# RockChip_RK3588 register map
Vendor: RockChip Electronics Co., Ltd.; Series: RK3588; File version: 0.1
Registers are 32-bit, read-write, no defined reset value unless marked. A register's access mark holds for its fields unless they carry their own. Offsets are from the block's base; [hi:lo] are bit positions; {n}, {i} and the like mark numbered series.

## CRU (part 3 of 6)
Base 0xFD7C0000
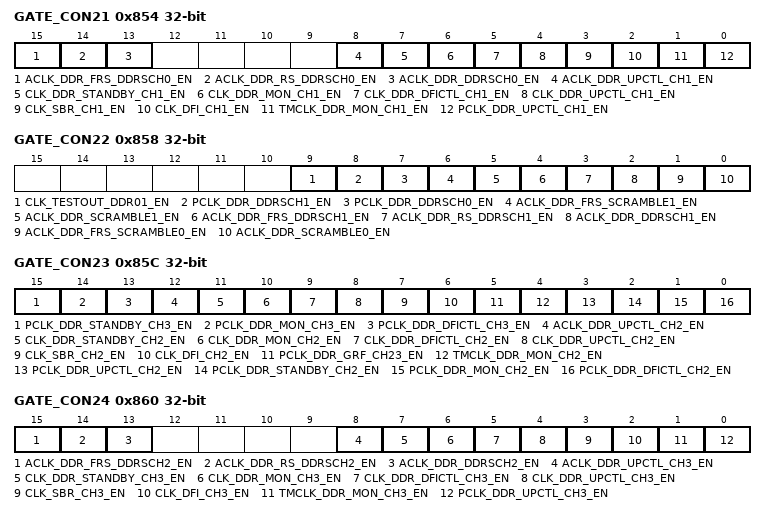
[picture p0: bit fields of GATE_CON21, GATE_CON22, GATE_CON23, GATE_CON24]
0x854 GATE_CON21 — Internal clock gate and division register 21
  [all] fields
    1=DISABLE; 0=ENABLE
  [15] ACLK_DDR_FRS_DDRSCH0_EN — aclk_ddr_frs_ddrsch0 clock gating control.
  [14] ACLK_DDR_RS_DDRSCH0_EN — aclk_ddr_rs_ddrsch0 clock gating control.
  [13] ACLK_DDR_DDRSCH0_EN — aclk_ddr_ddrsch0 clock gating control.
  [8] ACLK_DDR_UPCTL_CH1_EN — aclk_ddr_upctl_ch1 clock gating control.
  [7] CLK_DDR_STANDBY_CH1_EN — clk_ddr_standby_ch1 clock gating control.
  [6] CLK_DDR_MON_CH1_EN — clk_ddr_mon_ch1 clock gating control.
  [5] CLK_DDR_DFICTL_CH1_EN — clk_ddr_dfictl_ch1 clock gating control.
  [4] CLK_DDR_UPCTL_CH1_EN — clk_ddr_upctl_ch1 clock gating control.
  [3] CLK_SBR_CH1_EN — clk_sbr_ch1 clock gating control.
  [2] CLK_DFI_CH1_EN — clk_dfi_ch1 clock gating control.
  [1] TMCLK_DDR_MON_CH1_EN — tmclk_ddr_mon_ch1 clock gating control.
  [0] PCLK_DDR_UPCTL_CH1_EN — pclk_ddr_upctl_ch1 clock gating control.
0x858 GATE_CON22 — Internal clock gate and division register 22
  [all] fields
    1=DISABLE; 0=ENABLE
  [9] CLK_TESTOUT_DDR01_EN — clk_testout_ddr01 clock gating control.
  [8] PCLK_DDR_DDRSCH1_EN — pclk_ddr_ddrsch1 clock gating control.
  [7] PCLK_DDR_DDRSCH0_EN — pclk_ddr_ddrsch0 clock gating control.
  [6] ACLK_DDR_FRS_SCRAMBLE1_EN — aclk_ddr_frs_scramble1 clock gating control.
  [5] ACLK_DDR_SCRAMBLE1_EN — aclk_ddr_scramble1 clock gating control.
  [4] ACLK_DDR_FRS_DDRSCH1_EN — aclk_ddr_frs_ddrsch1 clock gating control.
  [3] ACLK_DDR_RS_DDRSCH1_EN — aclk_ddr_rs_ddrsch1 clock gating control.
  [2] ACLK_DDR_DDRSCH1_EN — aclk_ddr_ddrsch1 clock gating control.
  [1] ACLK_DDR_FRS_SCRAMBLE0_EN — aclk_ddr_frs_scramble0 clock gating control.
  [0] ACLK_DDR_SCRAMBLE0_EN — aclk_ddr_scramble0 clock gating control.
0x85C GATE_CON23 — Internal clock gate and division register 23
  [all] fields
    1=DISABLE; 0=ENABLE
  [15] PCLK_DDR_STANDBY_CH3_EN — pclk_ddr_standby_ch3 clock gating control.
  [14] PCLK_DDR_MON_CH3_EN — pclk_ddr_mon_ch3 clock gating control.
  [13] PCLK_DDR_DFICTL_CH3_EN — pclk_ddr_dfictl_ch3 clock gating control.
  [12] ACLK_DDR_UPCTL_CH2_EN — aclk_ddr_upctl_ch2 clock gating control.
  [11] CLK_DDR_STANDBY_CH2_EN — clk_ddr_standby_ch2 clock gating control.
  [10] CLK_DDR_MON_CH2_EN — clk_ddr_mon_ch2 clock gating control.
  [9] CLK_DDR_DFICTL_CH2_EN — clk_ddr_dfictl_ch2 clock gating control.
  [8] CLK_DDR_UPCTL_CH2_EN — clk_ddr_upctl_ch2 clock gating control.
  [7] CLK_SBR_CH2_EN — clk_sbr_ch2 clock gating control.
  [6] CLK_DFI_CH2_EN — clk_dfi_ch2 clock gating control.
  [5] PCLK_DDR_GRF_CH23_EN — pclk_ddr_grf_ch23 clock gating control, both ddr ch2 and ddr ch3.
  [4] TMCLK_DDR_MON_CH2_EN — tmclk_ddr_mon_ch2 clock gating control.
  [3] PCLK_DDR_UPCTL_CH2_EN — pclk_ddr_upctl_ch2 clock gating control.
  [2] PCLK_DDR_STANDBY_CH2_EN — pclk_ddr_standby_ch2 clock gating control.
  [1] PCLK_DDR_MON_CH2_EN — pclk_ddr_mon_ch2 clock gating control.
  [0] PCLK_DDR_DFICTL_CH2_EN — pclk_ddr_dfictl_ch2 clock gating control.
0x860 GATE_CON24 — Internal clock gate and division register 24
  [all] fields
    1=DISABLE; 0=ENABLE
  [15] ACLK_DDR_FRS_DDRSCH2_EN — aclk_ddr_frs_ddrsch2 clock gating control.
  [14] ACLK_DDR_RS_DDRSCH2_EN — aclk_ddr_rs_ddrsch2 clock gating control.
  [13] ACLK_DDR_DDRSCH2_EN — aclk_ddr_ddrsch2 clock gating control.
  [8] ACLK_DDR_UPCTL_CH3_EN — aclk_ddr_upctl_ch3 clock gating control.
  [7] CLK_DDR_STANDBY_CH3_EN — clk_ddr_standby_ch3 clock gating control.
  [6] CLK_DDR_MON_CH3_EN — clk_ddr_mon_ch3 clock gating control.
  [5] CLK_DDR_DFICTL_CH3_EN — clk_ddr_dfictl_ch3 clock gating control.
  [4] CLK_DDR_UPCTL_CH3_EN — clk_ddr_upctl_ch3 clock gating control.
  [3] CLK_SBR_CH3_EN — clk_sbr_ch3 clock gating control.
  [2] CLK_DFI_CH3_EN — clk_dfi_ch3 clock gating control.
  [1] TMCLK_DDR_MON_CH3_EN — tmclk_ddr_mon_ch3 clock gating control.
  [0] PCLK_DDR_UPCTL_CH3_EN — pclk_ddr_upctl_ch3 clock gating control.
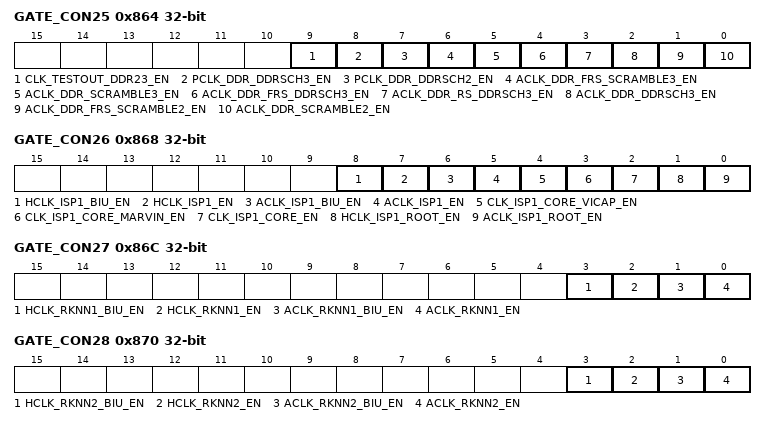
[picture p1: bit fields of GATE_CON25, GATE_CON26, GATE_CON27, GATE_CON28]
0x864 GATE_CON25 — Internal clock gate and division register 25
  [all] fields
    1=DISABLE; 0=ENABLE
  [9] CLK_TESTOUT_DDR23_EN — clk_testout_ddr23 clock gating control.
  [8] PCLK_DDR_DDRSCH3_EN — pclk_ddr_ddrsch3 clock gating control.
  [7] PCLK_DDR_DDRSCH2_EN — pclk_ddr_ddrsch2 clock gating control.
  [6] ACLK_DDR_FRS_SCRAMBLE3_EN — aclk_ddr_frs_scramble3 clock gating control.
  [5] ACLK_DDR_SCRAMBLE3_EN — aclk_ddr_scramble3 clock gating control.
  [4] ACLK_DDR_FRS_DDRSCH3_EN — aclk_ddr_frs_ddrsch3 clock gating control.
  [3] ACLK_DDR_RS_DDRSCH3_EN — aclk_ddr_rs_ddrsch3 clock gating control.
  [2] ACLK_DDR_DDRSCH3_EN — aclk_ddr_ddrsch3 clock gating control.
  [1] ACLK_DDR_FRS_SCRAMBLE2_EN — aclk_ddr_frs_scramble2 clock gating control.
  [0] ACLK_DDR_SCRAMBLE2_EN — aclk_ddr_scramble2 clock gating control.
0x868 GATE_CON26 — Internal clock gate and division register 26
  [all] fields
    1=DISABLE; 0=ENABLE
  [8] HCLK_ISP1_BIU_EN — hclk_isp1_biu clock gating control.
  [7] HCLK_ISP1_EN — hclk_isp1 clock gating control.
  [6] ACLK_ISP1_BIU_EN — aclk_isp1_biu clock gating control.
  [5] ACLK_ISP1_EN — aclk_isp1 clock gating control.
  [4] CLK_ISP1_CORE_VICAP_EN — clk_isp1_core_vicap clock gating control.
  [3] CLK_ISP1_CORE_MARVIN_EN — clk_isp1_core_marvin clock gating control.
  [2] CLK_ISP1_CORE_EN — clk_isp1_core clock gating control.
  [1] HCLK_ISP1_ROOT_EN — hclk_isp1_root clock gating control.
  [0] ACLK_ISP1_ROOT_EN — aclk_isp1_root clock gating control.
0x86C GATE_CON27 — Internal clock gate and division register 27
  [all] fields
    1=DISABLE; 0=ENABLE
  [3] HCLK_RKNN1_BIU_EN — hclk_rknn1_biu clock gating control.
  [2] HCLK_RKNN1_EN — hclk_rknn1 clock gating control.
  [1] ACLK_RKNN1_BIU_EN — aclk_rknn1_biu clock gating control.
  [0] ACLK_RKNN1_EN — aclk_rknn1 clock gating control.
0x870 GATE_CON28 — Internal clock gate and division register 28
  [all] fields
    1=DISABLE; 0=ENABLE
  [3] HCLK_RKNN2_BIU_EN — hclk_rknn2_biu clock gating control.
  [2] HCLK_RKNN2_EN — hclk_rknn2 clock gating control.
  [1] ACLK_RKNN2_BIU_EN — aclk_rknn2_biu clock gating control.
  [0] ACLK_RKNN2_EN — aclk_rknn2 clock gating control.
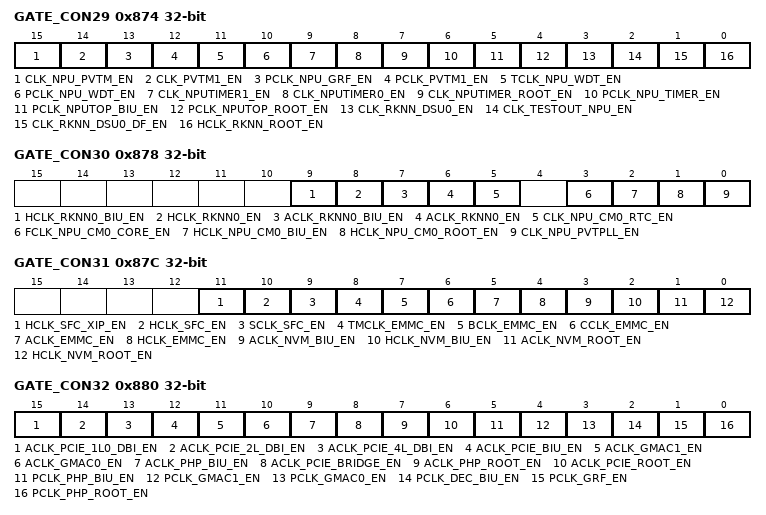
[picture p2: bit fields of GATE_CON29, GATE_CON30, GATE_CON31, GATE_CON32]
0x874 GATE_CON29 — Internal clock gate and division register 29
  [all] fields
    1=DISABLE; 0=ENABLE
  [15] CLK_NPU_PVTM_EN — clk_npu_pvtm clock gating control.
  [14] CLK_PVTM1_EN — clk_pvtm1 clock gating control.
  [13] PCLK_NPU_GRF_EN — pclk_npu_grf clock gating control.
  [12] PCLK_PVTM1_EN — pclk_pvtm1 clock gating control.
  [11] TCLK_NPU_WDT_EN — tclk_npu_wdt clock gating control.
  [10] PCLK_NPU_WDT_EN — pclk_npu_wdt clock gating control.
  [9] CLK_NPUTIMER1_EN — clk_nputimer1 clock gating control.
  [8] CLK_NPUTIMER0_EN — clk_nputimer0 clock gating control.
  [7] CLK_NPUTIMER_ROOT_EN — clk_nputimer_root clock gating control.
  [6] PCLK_NPU_TIMER_EN — pclk_npu_timer clock gating control.
  [5] PCLK_NPUTOP_BIU_EN — pclk_nputop_biu clock gating control.
  [4] PCLK_NPUTOP_ROOT_EN — pclk_nputop_root clock gating control.
  [3] CLK_RKNN_DSU0_EN — clk_rknn_dsu0 clock gating control.
  [2] CLK_TESTOUT_NPU_EN — clk_testout_npu clock gating control.
  [1] CLK_RKNN_DSU0_DF_EN — clk_rknn_dsu0_src_t clock gating control.
  [0] HCLK_RKNN_ROOT_EN — hclk_rknn_root clock gating control.
0x878 GATE_CON30 — Internal clock gate and division register 30
  [all] fields
    1=DISABLE; 0=ENABLE
  [9] HCLK_RKNN0_BIU_EN — hclk_rknn0_biu clock gating control.
  [8] HCLK_RKNN0_EN — hclk_rknn0 clock gating control.
  [7] ACLK_RKNN0_BIU_EN — aclk_rknn0_biu clock gating control.
  [6] ACLK_RKNN0_EN — aclk_rknn0 clock gating control.
  [5] CLK_NPU_CM0_RTC_EN — clk_npu_cm0_rtc clock gating control.
  [3] FCLK_NPU_CM0_CORE_EN — fclk_npu_cm0_core clock gating control.
  [2] HCLK_NPU_CM0_BIU_EN — hclk_npu_cm0_biu clock gating control.
  [1] HCLK_NPU_CM0_ROOT_EN — hclk_npu_cm0_root clock gating control.
  [0] CLK_NPU_PVTPLL_EN — clk_npu_pvtpll clock gating control.
0x87C GATE_CON31 — Internal clock gate and division register 31
  [all] fields
    1=DISABLE; 0=ENABLE
  [11] HCLK_SFC_XIP_EN — hclk_sfc_xip clock gating control.
  [10] HCLK_SFC_EN — hclk_sfc clock gating control.
  [9] SCLK_SFC_EN — sclk_sfc clock gating control.
  [8] TMCLK_EMMC_EN — tmclk_emmc clock gating control.
  [7] BCLK_EMMC_EN — bclk_emmc clock gating control.
  [6] CCLK_EMMC_EN — cclk_emmc clock gating control.
  [5] ACLK_EMMC_EN — aclk_emmc clock gating control.
  [4] HCLK_EMMC_EN — hclk_emmc clock gating control.
  [3] ACLK_NVM_BIU_EN — aclk_nvm_biu clock gating control.
  [2] HCLK_NVM_BIU_EN — hclk_nvm_biu clock gating control.
  [1] ACLK_NVM_ROOT_EN — aclk_nvm_root clock gating control.
  [0] HCLK_NVM_ROOT_EN — hclk_nvm_root clock gating control.
0x880 GATE_CON32 — Internal clock gate and division register 32
  [all] fields
    1=DISABLE; 0=ENABLE
  [15] ACLK_PCIE_1L0_DBI_EN — aclk_pcie_1l0_dbi clock gating control.
  [14] ACLK_PCIE_2L_DBI_EN — aclk_pcie_2l_dbi clock gating control.
  [13] ACLK_PCIE_4L_DBI_EN — aclk_pcie_4l_dbi clock gating control.
  [12] ACLK_PCIE_BIU_EN — aclk_pcie_biu clock gating control.
  [11] ACLK_GMAC1_EN — aclk_gmac1 clock gating control.
  [10] ACLK_GMAC0_EN — aclk_gmac0 clock gating control.
  [9] ACLK_PHP_BIU_EN — aclk_php_biu clock gating control.
  [8] ACLK_PCIE_BRIDGE_EN — aclk_pcie_gridge clock gating control.
  [7] ACLK_PHP_ROOT_EN — aclk_php_root clock gating control.
  [6] ACLK_PCIE_ROOT_EN — aclk_pcie_root clock gating control.
  [5] PCLK_PHP_BIU_EN — pclk_php_biu clock gating control.
  [4] PCLK_GMAC1_EN — pclk_gmac1 clock gating control.
  [3] PCLK_GMAC0_EN — pclk_gmac0 clock gating control.
  [2] PCLK_DEC_BIU_EN — pclk_dec_biu clock gating control.
  [1] PCLK_GRF_EN — pclk_grf clock gating control.
  [0] PCLK_PHP_ROOT_EN — pclk_php_root clock gating control.
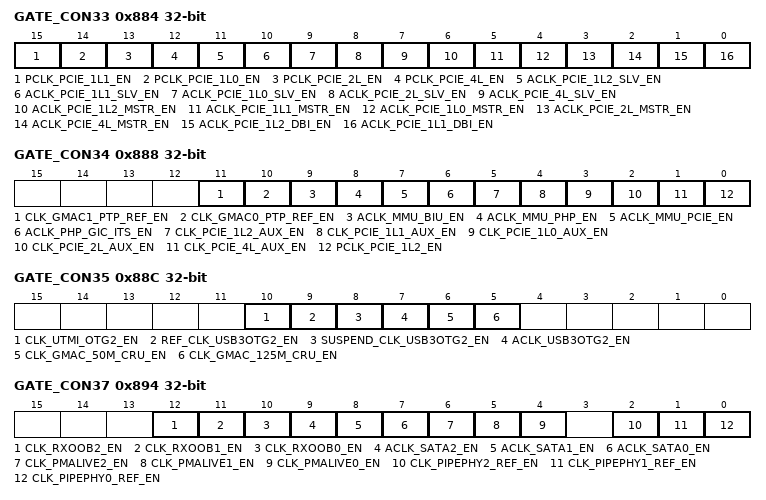
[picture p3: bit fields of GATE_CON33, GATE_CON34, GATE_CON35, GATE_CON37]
0x884 GATE_CON33 — Internal clock gate and division register 33
  [all] fields
    1=DISABLE; 0=ENABLE
  [15] PCLK_PCIE_1L1_EN — pclk_pcie_1l1 clock gating control.
  [14] PCLK_PCIE_1L0_EN — pclk_pcie_1l0 clock gating control.
  [13] PCLK_PCIE_2L_EN — pclk_pcie_2l clock gating control.
  [12] PCLK_PCIE_4L_EN — pclk_pcie_4l clock gating control.
  [11] ACLK_PCIE_1L2_SLV_EN — aclk_pcie_1l2_slv clock gating control.
  [10] ACLK_PCIE_1L1_SLV_EN — aclk_pcie_1l1_slv clock gating control.
  [9] ACLK_PCIE_1L0_SLV_EN — aclk_pcie_1l0_slv clock gating control.
  [8] ACLK_PCIE_2L_SLV_EN — aclk_pcie_2l_slv clock gating control.
  [7] ACLK_PCIE_4L_SLV_EN — aclk_pcie_4l_slv clock gating control.
  [6] ACLK_PCIE_1L2_MSTR_EN — aclk_pcie_1l2_mstr clock gating control.
  [5] ACLK_PCIE_1L1_MSTR_EN — aclk_pcie_1l1_mstr clock gating control.
  [4] ACLK_PCIE_1L0_MSTR_EN — aclk_pcie_1l0_mstr clock gating control.
  [3] ACLK_PCIE_2L_MSTR_EN — aclk_pcie_2l_mstr clock gating control.
  [2] ACLK_PCIE_4L_MSTR_EN — aclk_pcie_4l_mstr clock gating control.
  [1] ACLK_PCIE_1L2_DBI_EN — aclk_pcie_1l2_dbi clock gating control.
  [0] ACLK_PCIE_1L1_DBI_EN — aclk_pcie_1l1_dbi clock gating control.
0x888 GATE_CON34 — Internal clock gate and division register 34
  [all] fields
    1=DISABLE; 0=ENABLE
  [11] CLK_GMAC1_PTP_REF_EN — clk_gmac1_ptp_ref clock gating control.
  [10] CLK_GMAC0_PTP_REF_EN — clk_gmac0_ptp_ref clock gating control.
  [9] ACLK_MMU_BIU_EN — aclk_mmu_biu clock gating control.
  [8] ACLK_MMU_PHP_EN — aclk_mmu_php clock gating control.
  [7] ACLK_MMU_PCIE_EN — aclk_mmu_pcie clock gating control.
  [6] ACLK_PHP_GIC_ITS_EN — aclk_php_gic_its clock gating control.
  [5] CLK_PCIE_1L2_AUX_EN — clk_pcie_1l2_aux clock gating control.
  [4] CLK_PCIE_1L1_AUX_EN — clk_pcie_1l1_aux clock gating control.
  [3] CLK_PCIE_1L0_AUX_EN — clk_pcie_1l0_aux clock gating control.
  [2] CLK_PCIE_2L_AUX_EN — clk_pcie_2l_aux clock gating control.
  [1] CLK_PCIE_4L_AUX_EN — clk_pcie_4l_aux clock gating control.
  [0] PCLK_PCIE_1L2_EN — pclk_pcie_1l2 clock gating control.
0x88C GATE_CON35 — Internal clock gate and division register 35
  [all] fields
    1=DISABLE; 0=ENABLE
  [10] CLK_UTMI_OTG2_EN — clk_utmi_otg2 clock gating control.
  [9] REF_CLK_USB3OTG2_EN — ref_clk_usb3otg2 clock gating control.
  [8] SUSPEND_CLK_USB3OTG2_EN — suspend_clk_usb3otg2 clock gating control.
  [7] ACLK_USB3OTG2_EN — aclk_usb3otg2 clock gating control.
  [6] CLK_GMAC_50M_CRU_EN — clk_gmac_50m_cru_i clock gating control.
  [5] CLK_GMAC_125M_CRU_EN — clk_gmac_125m_cru_i clock gating control.
0x894 GATE_CON37 — Internal clock gate and division register 37
  [all] fields
    1=DISABLE; 0=ENABLE
  [12] CLK_RXOOB2_EN — clk_rxoob2 clock gating control.
  [11] CLK_RXOOB1_EN — clk_rxoob1 clock gating control.
  [10] CLK_RXOOB0_EN — clk_rxoob0 clock gating control.
  [9] ACLK_SATA2_EN — aclk_sata2 clock gating control.
  [8] ACLK_SATA1_EN — aclk_sata1 clock gating control.
  [7] ACLK_SATA0_EN — aclk_sata0 clock gating control.
  [6] CLK_PMALIVE2_EN — clk_pmalive2 clock gating control.
  [5] CLK_PMALIVE1_EN — clk_pmalive1 clock gating control.
  [4] CLK_PMALIVE0_EN — clk_pmalive0 clock gating control.
  [2] CLK_PIPEPHY2_REF_EN — clk_pipephy2_ref clock gating control.
  [1] CLK_PIPEPHY1_REF_EN — clk_pipephy1_ref clock gating control.
  [0] CLK_PIPEPHY0_REF_EN — clk_pipephy0_ref clock gating control.
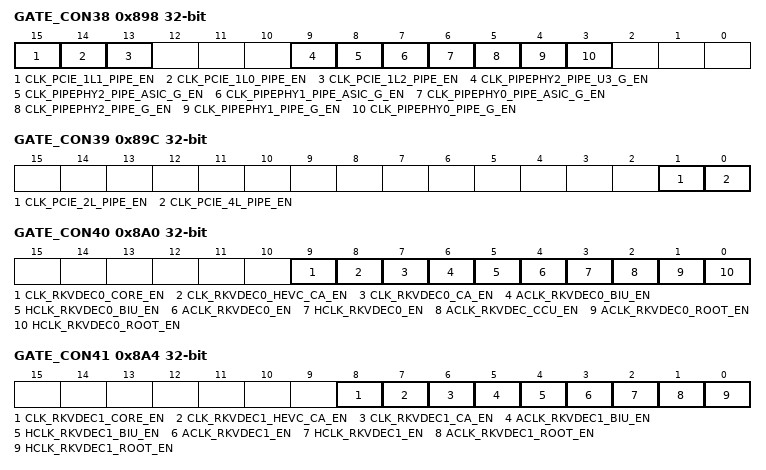
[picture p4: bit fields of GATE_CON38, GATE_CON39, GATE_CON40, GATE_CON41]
0x898 GATE_CON38 — Internal clock gate and division register 38
  [all] fields
    1=DISABLE; 0=ENABLE
  [15] CLK_PCIE_1L1_PIPE_EN — clk_pcie_1l1_pipe clock gating control.
  [14] CLK_PCIE_1L0_PIPE_EN — clk_pcie_1l0_pipe clock gating control.
  [13] CLK_PCIE_1L2_PIPE_EN — clk_pcie_1l2_pipe clock gating control.
  [9] CLK_PIPEPHY2_PIPE_U3_G_EN — clk_pipephy2_pipe_u3_g clock gating control.
  [8] CLK_PIPEPHY2_PIPE_ASIC_G_EN — clk_pipephy2_pipe_asic_g clock gating control.
  [7] CLK_PIPEPHY1_PIPE_ASIC_G_EN — clk_pipephy1_pipe_asic_g clock gating control.
  [6] CLK_PIPEPHY0_PIPE_ASIC_G_EN — clk_pipephy0_pipe_asic_g clock gating control.
  [5] CLK_PIPEPHY2_PIPE_G_EN — clk_pipephy2_pipe_g clock gating control.
  [4] CLK_PIPEPHY1_PIPE_G_EN — clk_pipephy1_pipe_g clock gating control.
  [3] CLK_PIPEPHY0_PIPE_G_EN — clk_pipephy0_pipe_g clock gating control.
0x89C GATE_CON39 — Internal clock gate and division register 39
  [1] CLK_PCIE_2L_PIPE_EN — clk_pcie_2l_pipe clock gating control.
    1=DISABLE; 0=ENABLE
  [0] CLK_PCIE_4L_PIPE_EN — clk_pcie_4l_pipe clock gating control.
    1=DISABLE; 0=ENABLE
0x8A0 GATE_CON40 — Internal clock gate and division register 40
  [all] fields
    1=DISABLE; 0=ENABLE
  [9] CLK_RKVDEC0_CORE_EN — clk_rkvdec0_core clock gating control.
  [8] CLK_RKVDEC0_HEVC_CA_EN — clk_rkvdec0_hevc_ca clock gating control.
  [7] CLK_RKVDEC0_CA_EN — clk_rkvdec0_ca clock gating control.
  [6] ACLK_RKVDEC0_BIU_EN — aclk_rkvdec0_biu clock gating control.
  [5] HCLK_RKVDEC0_BIU_EN — hclk_rkvdec0_biu clock gating control.
  [4] ACLK_RKVDEC0_EN — aclk_rkvdec0 clock gating control.
  [3] HCLK_RKVDEC0_EN — hclk_rkvdec0 clock gating control.
  [2] ACLK_RKVDEC_CCU_EN — aclk_rkvdec_ccu clock gating control.
  [1] ACLK_RKVDEC0_ROOT_EN — aclk_rkvdec0_root clock gating control.
  [0] HCLK_RKVDEC0_ROOT_EN — hclk_rkvdec0_root clock gating control.
0x8A4 GATE_CON41 — Internal clock gate and division register 41
  [all] fields
    1=DISABLE; 0=ENABLE
  [8] CLK_RKVDEC1_CORE_EN — clk_rkvdec1_core clock gating control.
  [7] CLK_RKVDEC1_HEVC_CA_EN — clk_rkvdec1_hevc_ca clock gating control.
  [6] CLK_RKVDEC1_CA_EN — clk_rkvdec1_ca clock gating control.
  [5] ACLK_RKVDEC1_BIU_EN — aclk_rkvdec1_biu clock gating control.
  [4] HCLK_RKVDEC1_BIU_EN — hclk_rkvdec1_biu clock gating control.
  [3] ACLK_RKVDEC1_EN — aclk_rkvdec1 clock gating control.
  [2] HCLK_RKVDEC1_EN — hclk_rkvdec1 clock gating control.
  [1] ACLK_RKVDEC1_ROOT_EN — aclk_rkvdec1_root clock gating control.
  [0] HCLK_RKVDEC1_ROOT_EN — hclk_rkvdec1_root clock gating control.
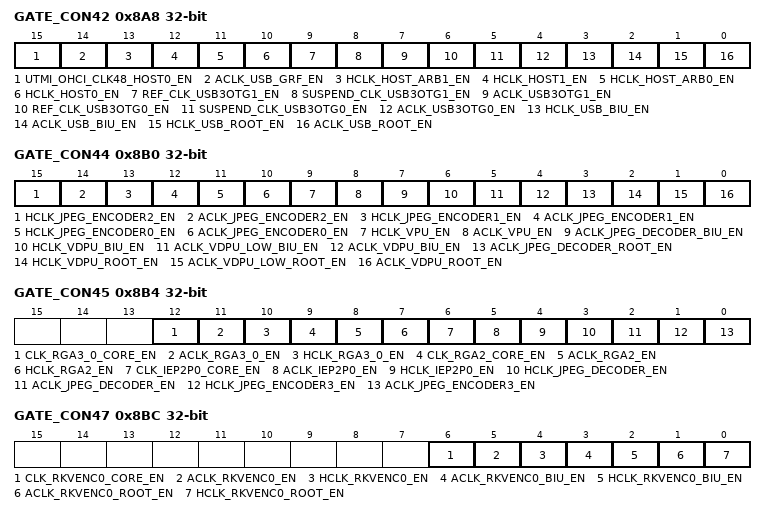
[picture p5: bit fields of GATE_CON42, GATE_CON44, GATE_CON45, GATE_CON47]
0x8A8 GATE_CON42 — Internal clock gate and division register 42
  [all] fields
    1=DISABLE; 0=ENABLE
  [15] UTMI_OHCI_CLK48_HOST0_EN — utmi_ohci_clk48_host0 clock gating control.
  [14] ACLK_USB_GRF_EN — aclk_usb_grf clock gating control.
  [13] HCLK_HOST_ARB1_EN — hclk_host_arb1 clock gating control.
  [12] HCLK_HOST1_EN — hclk_host1 clock gating control.
  [11] HCLK_HOST_ARB0_EN — hclk_host_arb0 clock gating control.
  [10] HCLK_HOST0_EN — hclk_host0 clock gating control.
  [9] REF_CLK_USB3OTG1_EN — ref_clk_usb3otg1 clock gating control.
  [8] SUSPEND_CLK_USB3OTG1_EN — suspend_clk_usb3otg1 clock gating control.
  [7] ACLK_USB3OTG1_EN — aclk_usb3otg1 clock gating control.
  [6] REF_CLK_USB3OTG0_EN — ref_clk_usb3otg0 clock gating control.
  [5] SUSPEND_CLK_USB3OTG0_EN — suspend_clk_usb3otg0 clock gating control.
  [4] ACLK_USB3OTG0_EN — aclk_usb3otg0 clock gating control.
  [3] HCLK_USB_BIU_EN — hclk_usb_biu clock gating control.
  [2] ACLK_USB_BIU_EN — aclk_usb_biu clock gating control.
  [1] HCLK_USB_ROOT_EN — hclk_usb_root clock gating control.
  [0] ACLK_USB_ROOT_EN — aclk_usb_root clock gating control.
0x8AC GATE_CON43 — Internal clock gate and division register 43
  [0] UTMI_OHCI_CLK48_HOST1_EN — utmi_ohci_clk48_host1 clock gating control.
    1=DISABLE; 0=ENABLE
0x8B0 GATE_CON44 — Internal clock gate and division register 44
  [all] fields
    1=DISABLE; 0=ENABLE
  [15] HCLK_JPEG_ENCODER2_EN — hclk_jpeg_encoder2 clock gating control.
  [14] ACLK_JPEG_ENCODER2_EN — aclk_jpeg_encoder2 clock gating control.
  [13] HCLK_JPEG_ENCODER1_EN — hclk_jpeg_encoder1 clock gating control.
  [12] ACLK_JPEG_ENCODER1_EN — aclk_jpeg_encoder1 clock gating control.
  [11] HCLK_JPEG_ENCODER0_EN — hclk_jpeg_encoder0 clock gating control.
  [10] ACLK_JPEG_ENCODER0_EN — aclk_jpeg_encoder0 clock gating control.
  [9] HCLK_VPU_EN — hclk_vpu clock gating control.
  [8] ACLK_VPU_EN — aclk_vpu clock gating control.
  [7] ACLK_JPEG_DECODER_BIU_EN — aclk_jpeg_decoder_biu clock gating control.
  [6] HCLK_VDPU_BIU_EN — hclk_vdpu_biu clock gating control.
  [5] ACLK_VDPU_LOW_BIU_EN — aclk_vdpu_low_biu clock gating control.
  [4] ACLK_VDPU_BIU_EN — aclk_vdpu_biu clock gating control.
  [3] ACLK_JPEG_DECODER_ROOT_EN — aclk_jpeg_decoder_root clock gating control.
  [2] HCLK_VDPU_ROOT_EN — hclk_vdpu_root clock gating control.
  [1] ACLK_VDPU_LOW_ROOT_EN — aclk_vdpu_low_root clock gating control.
  [0] ACLK_VDPU_ROOT_EN — aclk_vdpu_root clock gating control.
0x8B4 GATE_CON45 — Internal clock gate and division register 45
  [all] fields
    1=DISABLE; 0=ENABLE
  [12] CLK_RGA3_0_CORE_EN — clk_rga3_0_core clock gating control.
  [11] ACLK_RGA3_0_EN — aclk_rga3_0 clock gating control.
  [10] HCLK_RGA3_0_EN — hclk_rga3_0 clock gating control.
  [9] CLK_RGA2_CORE_EN — clk_rga2_core clock gating control.
  [8] ACLK_RGA2_EN — aclk_rga2 clock gating control.
  [7] HCLK_RGA2_EN — hclk_rga2 clock gating control.
  [6] CLK_IEP2P0_CORE_EN — clk_iep2p0_core clock gating control.
  [5] ACLK_IEP2P0_EN — aclk_iep2p0 clock gating control.
  [4] HCLK_IEP2P0_EN — hclk_iep2p0 clock gating control.
  [3] HCLK_JPEG_DECODER_EN — hclk_jpeg_decoder clock gating control.
  [2] ACLK_JPEG_DECODER_EN — aclk_jpeg_decoder clock gating control.
  [1] HCLK_JPEG_ENCODER3_EN — hclk_jpeg_encoder3 clock gating control.
  [0] ACLK_JPEG_ENCODER3_EN — aclk_jpeg_encoder3 clock gating control.
0x8BC GATE_CON47 — Internal clock gate and division register 47
  [all] fields
    1=DISABLE; 0=ENABLE
  [6] CLK_RKVENC0_CORE_EN — clk_rkvenc0_core clock gating control.
  [5] ACLK_RKVENC0_EN — aclk_rkvenc0 clock gating control.
  [4] HCLK_RKVENC0_EN — hclk_rkvenc0 clock gating control.
  [3] ACLK_RKVENC0_BIU_EN — aclk_rkvenc0_biu clock gating control.
  [2] HCLK_RKVENC0_BIU_EN — hclk_rkvenc0_biu clock gating control.
  [1] ACLK_RKVENC0_ROOT_EN — aclk_rkvenc0_root clock gating control.
  [0] HCLK_RKVENC0_ROOT_EN — hclk_rkvenc0_root clock gating control.
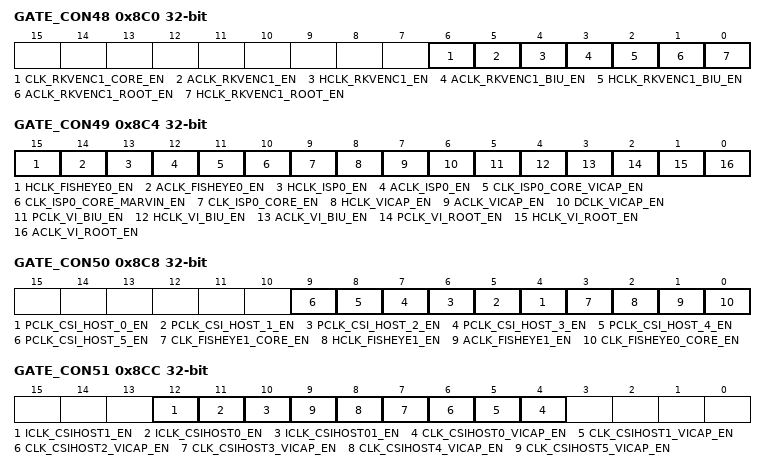
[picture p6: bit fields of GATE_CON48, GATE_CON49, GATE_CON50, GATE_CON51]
0x8C0 GATE_CON48 — Internal clock gate and division register 48
  [all] fields
    1=DISABLE; 0=ENABLE
  [6] CLK_RKVENC1_CORE_EN — clk_rkvenc1_core clock gating control.
  [5] ACLK_RKVENC1_EN — aclk_rkvenc1 clock gating control.
  [4] HCLK_RKVENC1_EN — hclk_rkvenc1 clock gating control.
  [3] ACLK_RKVENC1_BIU_EN — aclk_rkvenc1_biu clock gating control.
  [2] HCLK_RKVENC1_BIU_EN — hclk_rkvenc1_biu clock gating control.
  [1] ACLK_RKVENC1_ROOT_EN — aclk_rkvenc1_root clock gating control.
  [0] HCLK_RKVENC1_ROOT_EN — hclk_rkvenc1_root clock gating control.
0x8C4 GATE_CON49 — Internal clock gate and division register 49
  [all] fields
    1=DISABLE; 0=ENABLE
  [15] HCLK_FISHEYE0_EN — hclk_fisheye0 clock gating control.
  [14] ACLK_FISHEYE0_EN — aclk_fisheye0 clock gating control.
  [13] HCLK_ISP0_EN — hclk_isp0 clock gating control.
  [12] ACLK_ISP0_EN — aclk_isp0 clock gating control.
  [11] CLK_ISP0_CORE_VICAP_EN — clk_isp0_core_vicap clock gating control.
  [10] CLK_ISP0_CORE_MARVIN_EN — clk_isp0_core_marvin clock gating control.
  [9] CLK_ISP0_CORE_EN — clk_isp0_core clock gating control.
  [8] HCLK_VICAP_EN — hclk_vicap clock gating control.
  [7] ACLK_VICAP_EN — aclk_vicap clock gating control.
  [6] DCLK_VICAP_EN — dclk_vicap clock gating control.
  [5] PCLK_VI_BIU_EN — pclk_vi_biu clock gating control.
  [4] HCLK_VI_BIU_EN — hclk_vi_biu clock gating control.
  [3] ACLK_VI_BIU_EN — aclk_vi_biu clock gating control.
  [2] PCLK_VI_ROOT_EN — pclk_vi_root clock gating control.
  [1] HCLK_VI_ROOT_EN — hclk_vi_root clock gating control.
  [0] ACLK_VI_ROOT_EN — aclk_vi_root clock gating control.
0x8C8 GATE_CON50 — Internal clock gate and division register 50
  [all] fields
    1=DISABLE; 0=ENABLE
  [n+4] PCLK_CSI_HOST_{n}_EN (n=0..5) — pclk_csi_host_{n} clock gating control.
  [3] CLK_FISHEYE1_CORE_EN — clk_fisheye1_core clock gating control.
  [2] HCLK_FISHEYE1_EN — hclk_fisheye1 clock gating control.
  [1] ACLK_FISHEYE1_EN — aclk_fisheye1 clock gating control.
  [0] CLK_FISHEYE0_CORE_EN — clk_fisheye0_core clock gating control.
0x8CC GATE_CON51 — Internal clock gate and division register 51
  [all] fields
    1=DISABLE; 0=ENABLE
  [12] ICLK_CSIHOST1_EN — iclk_csihost1 clock gating control.
  [11] ICLK_CSIHOST0_EN — iclk_csihost0 clock gating control.
  [10] ICLK_CSIHOST01_EN — iclk_csihost01 clock gating control.
  [n+4] CLK_CSIHOST{n}_VICAP_EN (n=0..5) — clk_csihost{n}_vicap clock gating control.
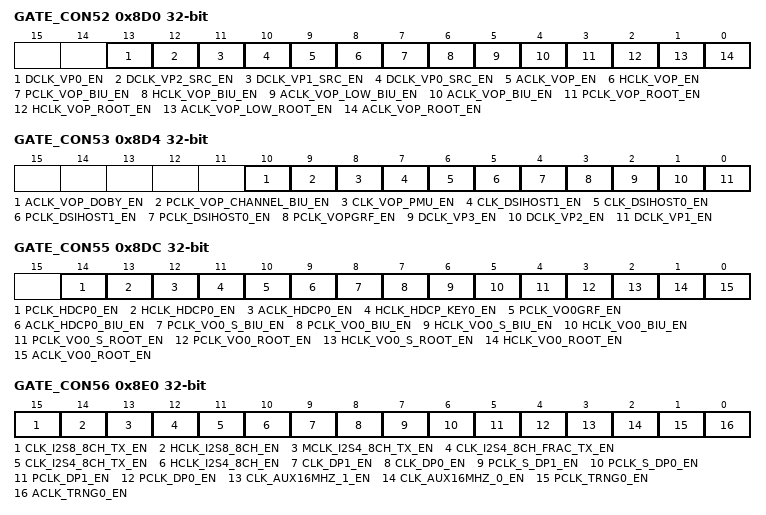
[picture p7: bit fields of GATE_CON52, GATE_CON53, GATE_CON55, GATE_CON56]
0x8D0 GATE_CON52 — Internal clock gate and division register 52
  [all] fields
    1=DISABLE; 0=ENABLE
  [13] DCLK_VP0_EN — dclk_vp0 clock gating control.
  [12] DCLK_VP2_SRC_EN — dclk_vp2_src clock gating control.
  [11] DCLK_VP1_SRC_EN — dclk_vp1_src clock gating control.
  [10] DCLK_VP0_SRC_EN — dclk_vp0_src clock gating control.
  [9] ACLK_VOP_EN — aclk_vop clock gating control.
  [8] HCLK_VOP_EN — hclk_vop clock gating control.
  [7] PCLK_VOP_BIU_EN — pclk_vop_biu clock gating control.
  [6] HCLK_VOP_BIU_EN — hclk_vop_biu clock gating control.
  [5] ACLK_VOP_LOW_BIU_EN — aclk_vop_low_biu clock gating control.
  [4] ACLK_VOP_BIU_EN — aclk_vop_biu clock gating control.
  [3] PCLK_VOP_ROOT_EN — pclk_vop_root clock gating control.
  [2] HCLK_VOP_ROOT_EN — hclk_vop_root clock gating control.
  [1] ACLK_VOP_LOW_ROOT_EN — aclk_vop_low_root clock gating control.
  [0] ACLK_VOP_ROOT_EN — aclk_vop_root clock gating control.
0x8D4 GATE_CON53 — Internal clock gate and division register 53
  [all] fields
    1=DISABLE; 0=ENABLE
  [10] ACLK_VOP_DOBY_EN — aclk_vop_doby clock gating control.
  [9] PCLK_VOP_CHANNEL_BIU_EN — pclk_vop_channel_biu clock gating control.
  [8] CLK_VOP_PMU_EN — clk_vop_pmu clock gating control.
  [7] CLK_DSIHOST1_EN — clk_dsihost1 clock gating control.
  [6] CLK_DSIHOST0_EN — clk_dsihost0 clock gating control.
  [5] PCLK_DSIHOST1_EN — pclk_dsihost1 clock gating control.
  [4] PCLK_DSIHOST0_EN — pclk_dsihost0 clock gating control.
  [3] PCLK_VOPGRF_EN — pclk_vopgrf clock gating control.
  [2] DCLK_VP3_EN — dclk_vp3 clock gating control.
  [1] DCLK_VP2_EN — dclk_vp2 clock gating control.
  [0] DCLK_VP1_EN — dclk_vp1 clock gating control.
0x8DC GATE_CON55 — Internal clock gate and division register 55
  [all] fields
    1=DISABLE; 0=ENABLE
  [14] PCLK_HDCP0_EN — pclk_hdcp0 clock gating control.
  [13] HCLK_HDCP0_EN — hclk_hdcp0 clock gating control.
  [12] ACLK_HDCP0_EN — aclk_hdcp0 clock gating control.
  [11] HCLK_HDCP_KEY0_EN — hclk_hdcp_key0 clock gating control.
  [10] PCLK_VO0GRF_EN — pclk_vo0grf clock gating control.
  [9] ACLK_HDCP0_BIU_EN — aclk_hdcp0_biu clock gating control.
  [8] PCLK_VO0_S_BIU_EN — pclk_vo0_s_biu clock gating control.
  [7] PCLK_VO0_BIU_EN — pclk_vo0_biu clock gating control.
  [6] HCLK_VO0_S_BIU_EN — hclk_vo0_s_biu clock gating control.
  [5] HCLK_VO0_BIU_EN — hclk_vo0_biu clock gating control.
  [4] PCLK_VO0_S_ROOT_EN — pclk_vo0_s_root clock gating control.
  [3] PCLK_VO0_ROOT_EN — pclk_vo0_root clock gating control.
  [2] HCLK_VO0_S_ROOT_EN — hclk_vo0_s_root clock gating control.
  [1] HCLK_VO0_ROOT_EN — hclk_vo0_root clock gating control.
  [0] ACLK_VO0_ROOT_EN — aclk_vo0_root clock gating control.
0x8E0 GATE_CON56 — Internal clock gate and division register 56
  [all] fields
    1=DISABLE; 0=ENABLE
  [15] CLK_I2S8_8CH_TX_EN — clk_i2s8_8ch_tx_src clock gating control.
  [14] HCLK_I2S8_8CH_EN — hclk_i2s8_8ch clock gating control.
  [13] MCLK_I2S4_8CH_TX_EN — mclk_i2s4_8ch_tx clock gating control.
  [12] CLK_I2S4_8CH_FRAC_TX_EN — clk_i2s4_8ch_tx_frac clock gating control.
  [11] CLK_I2S4_8CH_TX_EN — clk_i2s4_8ch_tx_src clock gating control.
  [10] HCLK_I2S4_8CH_EN — hclk_i2s4_8ch clock gating control.
  [9] CLK_DP1_EN — clk_dp1 clock gating control.
  [8] CLK_DP0_EN — clk_dp0 clock gating control.
  [7] PCLK_S_DP1_EN — pclk_s_dp1 clock gating control.
  [6] PCLK_S_DP0_EN — pclk_s_dp0 clock gating control.
  [5] PCLK_DP1_EN — pclk_dp1 clock gating control.
  [4] PCLK_DP0_EN — pclk_dp0 clock gating control.
  [3] CLK_AUX16MHZ_1_EN — clk_aux16mhz_1 clock gating control.
  [2] CLK_AUX16MHZ_0_EN — clk_aux16mhz_0 clock gating control.
  [1] PCLK_TRNG0_EN — pclk_trng0 clock gating control.
  [0] ACLK_TRNG0_EN — aclk_trng0 clock gating control.
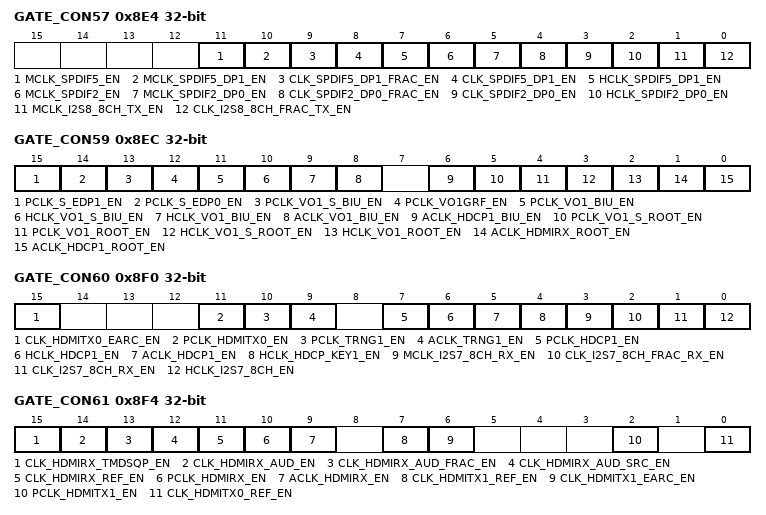
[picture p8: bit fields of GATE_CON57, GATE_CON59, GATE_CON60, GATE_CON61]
0x8E4 GATE_CON57 — Internal clock gate and division register 57
  [all] fields
    1=DISABLE; 0=ENABLE
  [11] MCLK_SPDIF5_EN — mclk_spdif5 clock gating control.
  [10] MCLK_SPDIF5_DP1_EN — mclk_spdif5_dp1 clock gating control.
  [9] CLK_SPDIF5_DP1_FRAC_EN — clk_spdif5_dp1_frac clock gating control.
  [8] CLK_SPDIF5_DP1_EN — clk_spdif5_dp1_src clock gating control.
  [7] HCLK_SPDIF5_DP1_EN — hclk_spdif5_dp1 clock gating control.
  [6] MCLK_SPDIF2_EN — mclk_spdif2 clock gating control.
  [5] MCLK_SPDIF2_DP0_EN — mclk_spdif2_dp0 clock gating control.
  [4] CLK_SPDIF2_DP0_FRAC_EN — clk_spdif2_dp0_frac clock gating control.
  [3] CLK_SPDIF2_DP0_EN — clk_spdif2_dp0_src clock gating control.
  [2] HCLK_SPDIF2_DP0_EN — hclk_spdif2_dp0 clock gating control.
  [1] MCLK_I2S8_8CH_TX_EN — mclk_i2s8_8ch_tx clock gating control.
  [0] CLK_I2S8_8CH_FRAC_TX_EN — clk_i2s8_8ch_tx_frac clock gating control.
0x8EC GATE_CON59 — Internal clock gate and division register 59
  [all] fields
    1=DISABLE; 0=ENABLE
  [15] PCLK_S_EDP1_EN — pclk_s_edp1 clock gating control.
  [14] PCLK_S_EDP0_EN — pclk_s_edp0 clock gating control.
  [13] PCLK_VO1_S_BIU_EN — pclk_vo1_s_biu clock gating control.
  [12] PCLK_VO1GRF_EN — pclk_vo1grf clock gating control.
  [11] PCLK_VO1_BIU_EN — pclk_vo1_biu clock gating control.
  [10] HCLK_VO1_S_BIU_EN — hclk_vo1_s_biu clock gating control.
  [9] HCLK_VO1_BIU_EN — hclk_vo1_biu clock gating control.
  [8] ACLK_VO1_BIU_EN — aclk_vo1_biu clock gating control.
  [6] ACLK_HDCP1_BIU_EN — aclk_hdcp1_biu clock gating control.
  [5] PCLK_VO1_S_ROOT_EN — pclk_vo1_s_root clock gating control.
  [4] PCLK_VO1_ROOT_EN — pclk_vo1_root clock gating control.
  [3] HCLK_VO1_S_ROOT_EN — hclk_vo1_s_root clock gating control.
  [2] HCLK_VO1_ROOT_EN — hclk_vo1_root clock gating control.
  [1] ACLK_HDMIRX_ROOT_EN — aclk_hdmirx_root clock gating control.
  [0] ACLK_HDCP1_ROOT_EN — aclk_hdcp1_root clock gating control.
0x8F0 GATE_CON60 — Internal clock gate and division register 60
  [all] fields
    1=DISABLE; 0=ENABLE
  [15] CLK_HDMITX0_EARC_EN — clk_hdmitx0_earc clock gating control.
  [11] PCLK_HDMITX0_EN — pclk_hdmitx0 clock gating control.
  [10] PCLK_TRNG1_EN — pclk_trng1 clock gating control.
  [9] ACLK_TRNG1_EN — aclk_trng1 clock gating control.
  [7] PCLK_HDCP1_EN — pclk_hdcp1 clock gating control.
  [6] HCLK_HDCP1_EN — hclk_hdcp1 clock gating control.
  [5] ACLK_HDCP1_EN — aclk_hdcp1 clock gating control.
  [4] HCLK_HDCP_KEY1_EN — hclk_hdcp_key1 clock gating control.
  [3] MCLK_I2S7_8CH_RX_EN — mclk_i2s7_8ch_rx clock gating control.
  [2] CLK_I2S7_8CH_FRAC_RX_EN — clk_i2s7_8ch_rx_frac clock gating control.
  [1] CLK_I2S7_8CH_RX_EN — clk_i2s7_8ch_rx_src clock gating control.
  [0] HCLK_I2S7_8CH_EN — hclk_i2s7_8ch clock gating control.
0x8F4 GATE_CON61 — Internal clock gate and division register 61
  [all] fields
    1=DISABLE; 0=ENABLE
  [15] CLK_HDMIRX_TMDSQP_EN — clk_hdmirx_tmdsqp clock gating control.
  [14] CLK_HDMIRX_AUD_EN — clk_hdmirx_aud clock gating control.
  [13] CLK_HDMIRX_AUD_FRAC_EN — clk_hdmirx_aud_frac clock gating control.
  [12] CLK_HDMIRX_AUD_SRC_EN — clk_hdmirx_aud_src clock gating control.
  [11] CLK_HDMIRX_REF_EN — clk_hdmirx_ref clock gating control.
  [10] PCLK_HDMIRX_EN — pclk_hdmirx clock gating control.
  [9] ACLK_HDMIRX_EN — aclk_hdmirx clock gating control.
  [7] CLK_HDMITX1_REF_EN — clk_hdmitx1_ref clock gating control.
  [6] CLK_HDMITX1_EARC_EN — clk_hdmitx1_earc clock gating control.
  [2] PCLK_HDMITX1_EN — pclk_hdmitx1 clock gating control.
  [0] CLK_HDMITX0_REF_EN — clk_hdmitx0_ref clock gating control.
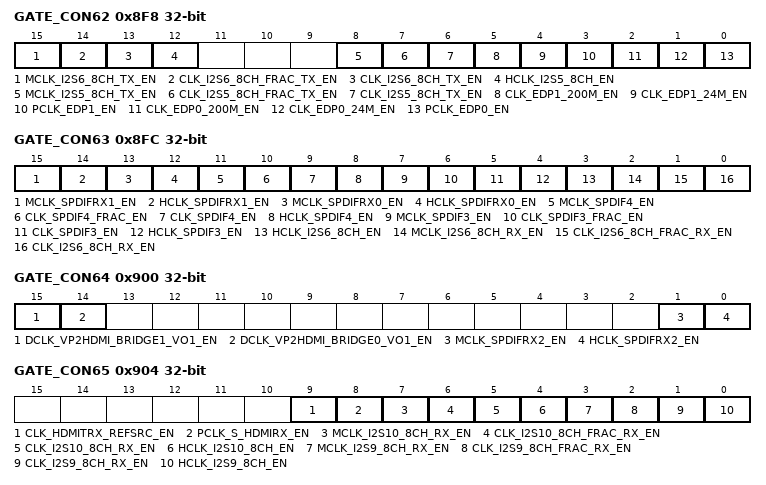
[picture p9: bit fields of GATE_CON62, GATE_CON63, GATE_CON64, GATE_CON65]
0x8F8 GATE_CON62 — Internal clock gate and division register 62
  [all] fields
    1=DISABLE; 0=ENABLE
  [15] MCLK_I2S6_8CH_TX_EN — mclk_i2s6_8ch_tx clock gating control.
  [14] CLK_I2S6_8CH_FRAC_TX_EN — clk_i2s6_8ch_tx_frac clock gating control.
  [13] CLK_I2S6_8CH_TX_EN — clk_i2s6_8ch_tx_src clock gating control.
  [12] HCLK_I2S5_8CH_EN — hclk_i2s5_8ch clock gating control.
  [8] MCLK_I2S5_8CH_TX_EN — mclk_i2s5_8ch_tx clock gating control.
  [7] CLK_I2S5_8CH_FRAC_TX_EN — clk_i2s5_8ch_tx_frac clock gating control.
  [6] CLK_I2S5_8CH_TX_EN — clk_i2s5_8ch_tx_src clock gating control.
  [5] CLK_EDP1_200M_EN — clk_edp1_200m clock gating control.
  [4] CLK_EDP1_24M_EN — clk_edp1_24m clock gating control.
  [3] PCLK_EDP1_EN — pclk_edp1 clock gating control.
  [2] CLK_EDP0_200M_EN — clk_edp0_200m clock gating control.
  [1] CLK_EDP0_24M_EN — clk_edp0_24m clock gating control.
  [0] PCLK_EDP0_EN — pclk_edp0 clock gating control.
0x8FC GATE_CON63 — Internal clock gate and division register 63
  [all] fields
    1=DISABLE; 0=ENABLE
  [15] MCLK_SPDIFRX1_EN — mclk_spdifrx1 clock gating control.
  [14] HCLK_SPDIFRX1_EN — hclk_spdifrx1 clock gating control.
  [13] MCLK_SPDIFRX0_EN — mclk_spdifrx0 clock gating control.
  [12] HCLK_SPDIFRX0_EN — hclk_spdifrx0 clock gating control.
  [11] MCLK_SPDIF4_EN — mclk_spdif4 clock gating control.
  [10] CLK_SPDIF4_FRAC_EN — clk_spdif4_frac clock gating control.
  [9] CLK_SPDIF4_EN — clk_spdif4_src clock gating control.
  [8] HCLK_SPDIF4_EN — hclk_spdif4 clock gating control.
  [7] MCLK_SPDIF3_EN — mclk_spdif3 clock gating control.
  [6] CLK_SPDIF3_FRAC_EN — clk_spdif3_frac clock gating control.
  [5] CLK_SPDIF3_EN — clk_spdif3_src clock gating control.
  [4] HCLK_SPDIF3_EN — hclk_spdif3 clock gating control.
  [3] HCLK_I2S6_8CH_EN — hclk_i2s6_8ch clock gating control.
  [2] MCLK_I2S6_8CH_RX_EN — mclk_i2s6_8ch_rx clock gating control.
  [1] CLK_I2S6_8CH_FRAC_RX_EN — clk_i2s6_8ch_rx_frac clock gating control.
  [0] CLK_I2S6_8CH_RX_EN — clk_i2s6_8ch_rx_src clock gating control.
0x900 GATE_CON64 — Internal clock gate and division register 64
  [all] fields
    1=DISABLE; 0=ENABLE
  [15] DCLK_VP2HDMI_BRIDGE1_VO1_EN — dclk_vp2hdmi_bridge1_vo1 clock gating control.
  [14] DCLK_VP2HDMI_BRIDGE0_VO1_EN — dclk_vp2hdmi_bridge0_vo1 clock gating control.
  [1] MCLK_SPDIFRX2_EN — mclk_spdifrx2 clock gating control.
  [0] HCLK_SPDIFRX2_EN — hclk_spdifrx2 clock gating control.
0x904 GATE_CON65 — Internal clock gate and division register 65
  [all] fields
    1=DISABLE; 0=ENABLE
  [9] CLK_HDMITRX_REFSRC_EN — clk_hdmitrx_refsrc clock gating control.
  [8] PCLK_S_HDMIRX_EN — pclk_s_hdmirx clock gating control.
  [7] MCLK_I2S10_8CH_RX_EN — mclk_i2s10_8ch_rx clock gating control.
  [6] CLK_I2S10_8CH_FRAC_RX_EN — clk_i2s10_8ch_rx_frac clock gating control.
  [5] CLK_I2S10_8CH_RX_EN — clk_i2s10_8ch_rx_src clock gating control.
  [4] HCLK_I2S10_8CH_EN — hclk_i2s10_8ch clock gating control.
  [3] MCLK_I2S9_8CH_RX_EN — mclk_i2s9_8ch_rx clock gating control.
  [2] CLK_I2S9_8CH_FRAC_RX_EN — clk_i2s9_8ch_rx_frac clock gating control.
  [1] CLK_I2S9_8CH_RX_EN — clk_i2s9_8ch_rx_src clock gating control.
  [0] HCLK_I2S9_8CH_EN — hclk_i2s9_8ch clock gating control.
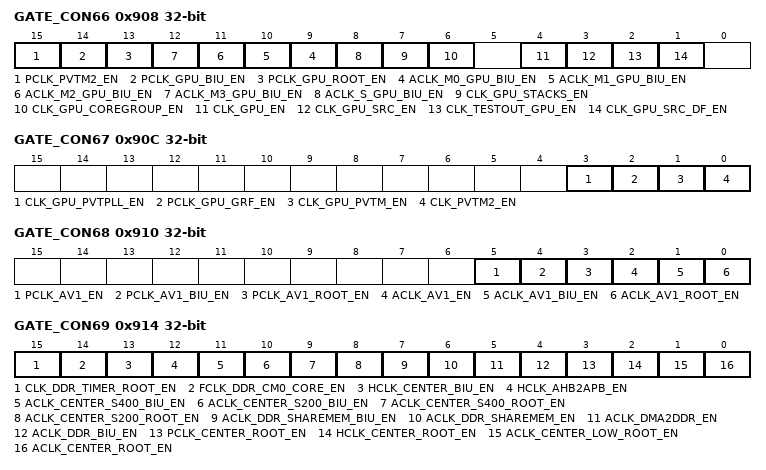
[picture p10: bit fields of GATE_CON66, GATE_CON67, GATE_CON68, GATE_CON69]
0x908 GATE_CON66 — Internal clock gate and division register 66
  [all] fields
    1=DISABLE; 0=ENABLE
  [15] PCLK_PVTM2_EN — pclk_pvtm2 clock gating control.
  [14] PCLK_GPU_BIU_EN — pclk_gpu_biu clock gating control.
  [13] PCLK_GPU_ROOT_EN — pclk_gpu_root clock gating control.
  [n+9] ACLK_M{n}_GPU_BIU_EN (n=0..3) — aclk_m{n}_gpu_biu clock gating control.
  [8] ACLK_S_GPU_BIU_EN — aclk_s_gpu_biu clock gating control.
  [7] CLK_GPU_STACKS_EN — clk_gpu_stacks clock gating control.
  [6] CLK_GPU_COREGROUP_EN — clk_gpu_coregroup clock gating control.
  [4] CLK_GPU_EN — clk_gpu clock gating control.
  [3] CLK_GPU_SRC_EN — clk_gpu_src clock gating control.
  [2] CLK_TESTOUT_GPU_EN — clk_testout_gpu clock gating control.
  [1] CLK_GPU_SRC_DF_EN — clk_gpu_src_t clock gating control.
0x90C GATE_CON67 — Internal clock gate and division register 67
  [all] fields
    1=DISABLE; 0=ENABLE
  [3] CLK_GPU_PVTPLL_EN — clk_gpu_pvtpll clock gating control.
  [2] PCLK_GPU_GRF_EN — pclk_gpu_grf clock gating control.
  [1] CLK_GPU_PVTM_EN — clk_gpu_pvtm clock gating control.
  [0] CLK_PVTM2_EN — clk_pvtm2 clock gating control.
0x910 GATE_CON68 — Internal clock gate and division register 68
  [all] fields
    1=DISABLE; 0=ENABLE
  [5] PCLK_AV1_EN — pclk_av1 clock gating control.
  [4] PCLK_AV1_BIU_EN — pclk_av1_biu clock gating control.
  [3] PCLK_AV1_ROOT_EN — pclk_av1_root clock gating control.
  [2] ACLK_AV1_EN — aclk_av1 clock gating control.
  [1] ACLK_AV1_BIU_EN — aclk_av1_biu clock gating control.
  [0] ACLK_AV1_ROOT_EN — aclk_av1_root clock gating control.
0x914 GATE_CON69 — Internal clock gate and division register 69
  [all] fields
    1=DISABLE; 0=ENABLE
  [15] CLK_DDR_TIMER_ROOT_EN — clk_ddr_timer_root clock gating control.
  [14] FCLK_DDR_CM0_CORE_EN — fclk_ddr_cm0_core clock gating control.
  [13] HCLK_CENTER_BIU_EN — hclk_center_biu clock gating control.
  [12] HCLK_AHB2APB_EN — hclk_ahb2apb clock gating control.
  [11] ACLK_CENTER_S400_BIU_EN — aclk_center_s400_biu clock gating control.
  [10] ACLK_CENTER_S200_BIU_EN — aclk_center_s200_biu clock gating control.
  [9] ACLK_CENTER_S400_ROOT_EN — aclk_center_s400_root clock gating control.
  [8] ACLK_CENTER_S200_ROOT_EN — aclk_center_s200_root clock gating control.
  [7] ACLK_DDR_SHAREMEM_BIU_EN — aclk_ddr_sharemem_biu clock gating control.
  [6] ACLK_DDR_SHAREMEM_EN — aclk_ddr_sharemem clock gating control.
  [5] ACLK_DMA2DDR_EN — aclk_dma2ddr clock gating control.
  [4] ACLK_DDR_BIU_EN — aclk_ddr_biu clock gating control.
  [3] PCLK_CENTER_ROOT_EN — pclk_center_root clock gating control.
  [2] HCLK_CENTER_ROOT_EN — hclk_center_root clock gating control.
  [1] ACLK_CENTER_LOW_ROOT_EN — aclk_center_low_root clock gating control.
  [0] ACLK_CENTER_ROOT_EN — aclk_center_root clock gating control.
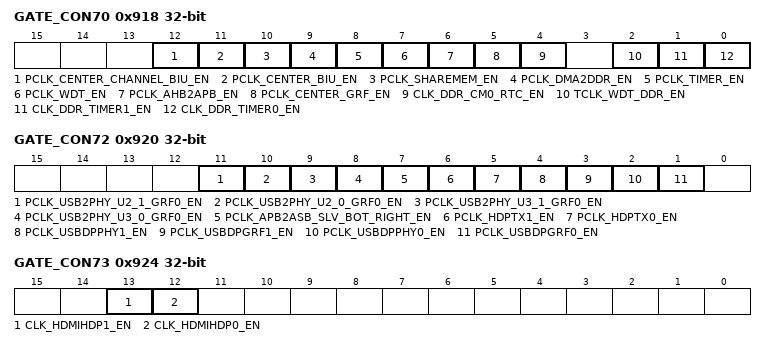
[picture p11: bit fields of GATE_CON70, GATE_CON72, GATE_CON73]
0x918 GATE_CON70 — Internal clock gate and division register 70
  [all] fields
    1=DISABLE; 0=ENABLE
  [12] PCLK_CENTER_CHANNEL_BIU_EN — pclk_center_channel_biu clock gating control.
  [11] PCLK_CENTER_BIU_EN — pclk_center_biu clock gating control.
  [10] PCLK_SHAREMEM_EN — pclk_sharemem clock gating control.
  [9] PCLK_DMA2DDR_EN — pclk_dma2ddr clock gating control.
  [8] PCLK_TIMER_EN — pclk_timer clock gating control.
  [7] PCLK_WDT_EN — pclk_wdt clock gating control.
  [6] PCLK_AHB2APB_EN — pclk_ahb2apb clock gating control.
  [5] PCLK_CENTER_GRF_EN — pclk_center_grf clock gating control.
  [4] CLK_DDR_CM0_RTC_EN — clk_ddr_cm0_rtc clock gating control.
  [2] TCLK_WDT_DDR_EN — tclk_wdt_ddr clock gating control.
  [1] CLK_DDR_TIMER1_EN — clk_ddr_timer1 clock gating control.
  [0] CLK_DDR_TIMER0_EN — clk_ddr_timer0 clock gating control.
0x920 GATE_CON72 — Internal clock gate and division register 72
  [all] fields
    1=DISABLE; 0=ENABLE
  [11] PCLK_USB2PHY_U2_1_GRF0_EN — pclk_usb2phy_u2_1_grf0 clock gating control.
  [10] PCLK_USB2PHY_U2_0_GRF0_EN — pclk_usb2phy_u2_0_grf0 clock gating control.
  [9] PCLK_USB2PHY_U3_1_GRF0_EN — pclk_usb2phy_u3_1_grf0 clock gating control.
  [8] PCLK_USB2PHY_U3_0_GRF0_EN — pclk_usb2phy_u3_0_grf0 clock gating control.
  [7] PCLK_APB2ASB_SLV_BOT_RIGHT_EN — pclk_apb2asb_slv_bot_right clock gating control.
  [6] PCLK_HDPTX1_EN — pclk_hdptx1 clock gating control.
  [5] PCLK_HDPTX0_EN — pclk_hdptx0 clock gating control.
  [4] PCLK_USBDPPHY1_EN — pclk_usbdpphy1 clock gating control.
  [3] PCLK_USBDPGRF1_EN — pclk_usbdpgrf1 clock gating control.
  [2] PCLK_USBDPPHY0_EN — pclk_usbdpphy0 clock gating control.
  [1] PCLK_USBDPGRF0_EN — pclk_usbdpgrf0 clock gating control.
0x924 GATE_CON73 — Internal clock gate and division register 73
  [13] CLK_HDMIHDP1_EN — clk_hdmihdp1 clock gating control.
    1=DISABLE; 0=ENABLE
  [12] CLK_HDMIHDP0_EN — clk_hdmihdp0 clock gating control.
    1=DISABLE; 0=ENABLE
